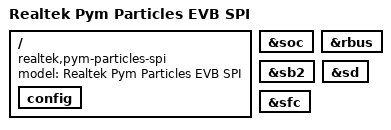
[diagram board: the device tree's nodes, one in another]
// SPDX-License-Identifier: (GPL-2.0-or-later OR BSD-2-Clause)
/*
 * Copyright (c) 2019-2020 Realtek Semiconductor Corp.
 */

/dts-v1/;

#include "rtd1319-pymparticles.dtsi"

/ {
	compatible = "realtek,pym-particles-spi", "realtek,rtd1319";
	model = "Realtek Pym Particles EVB SPI";

	config {
		//u-boot,spl-payload-offset = <0xA0000>; /* @ 640KB */
	};
};

&soc {
	bootph-all;
};

&rbus {
	bootph-all;
};

&sb2 {
	bootph-all;
};

&sd {
	bootph-all;
	status = "okay";
};

&sfc {
	bootph-all;
	status = "okay";
};
